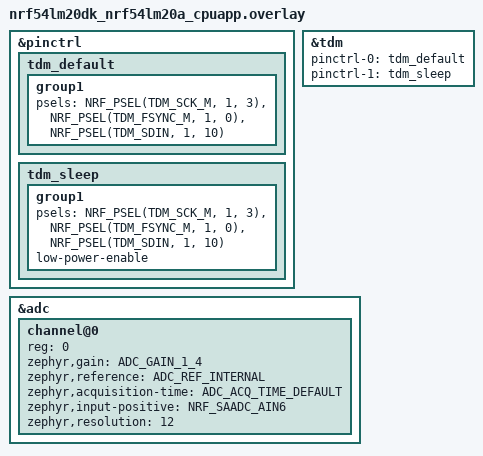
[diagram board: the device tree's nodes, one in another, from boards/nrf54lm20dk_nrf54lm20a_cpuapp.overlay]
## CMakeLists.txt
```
cmake_minimum_required(VERSION 3.20.0)
find_package(Zephyr REQUIRED HINTS $ENV{ZEPHYR_BASE})
project(kaitek_adc_test)
target_sources(app PRIVATE src/main.c)
```

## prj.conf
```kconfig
CONFIG_I2S=y
CONFIG_LOG=y
CONFIG_LOG_DEFAULT_LEVEL=3
CONFIG_MAIN_STACK_SIZE=4096
CONFIG_LOG_BACKEND_UART=y
CONFIG_UART_CONSOLE=y
CONFIG_ADC=y
CONFIG_ADC_NRFX_SAADC=y
```

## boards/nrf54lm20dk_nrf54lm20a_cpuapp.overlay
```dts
&pinctrl {
    tdm_default: tdm_default {
        group1 {
            psels = <NRF_PSEL(TDM_SCK_M, 1, 3)>,
                    <NRF_PSEL(TDM_FSYNC_M, 1, 0)>,
                    <NRF_PSEL(TDM_SDIN, 1, 10)>;
        };
    };
    tdm_sleep: tdm_sleep {
        group1 {
            psels = <NRF_PSEL(TDM_SCK_M, 1, 3)>,
                    <NRF_PSEL(TDM_FSYNC_M, 1, 0)>,
                    <NRF_PSEL(TDM_SDIN, 1, 10)>;
            low-power-enable;
        };
    };
};

&tdm {
    status = "okay";
    pinctrl-0 = <&tdm_default>;
    pinctrl-1 = <&tdm_sleep>;
    pinctrl-names = "default", "sleep";
};

&adc {
    status = "okay";
    #address-cells = <1>;
    #size-cells = <0>;

    channel@0 {
        reg = <0>;
        zephyr,gain = "ADC_GAIN_1_4";
        zephyr,reference = "ADC_REF_INTERNAL";
        zephyr,acquisition-time = <ADC_ACQ_TIME_DEFAULT>;
        zephyr,input-positive = <NRF_SAADC_AIN6>;  /* P1.04 */
        zephyr,resolution = <12>;
    };
};
```

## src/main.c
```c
#include <zephyr/kernel.h>
#include <zephyr/drivers/adc.h>
#include <zephyr/dt-bindings/adc/nrf-saadc.h>
#include <zephyr/logging/log.h>

LOG_MODULE_REGISTER(piezo_adc, LOG_LEVEL_INF);

#define ADC_NODE       DT_NODELABEL(adc)
#define ADC_CHANNEL    0
#define ADC_RESOLUTION 12
#define VREF_MV        600
#define VREF_GAIN      ADC_GAIN_1_4

static const struct device *adc_dev;
static int16_t sample_buffer;

static const struct adc_channel_cfg ch_cfg = {
    .gain             = ADC_GAIN_1_4,
    .reference        = ADC_REF_INTERNAL,
    .acquisition_time = ADC_ACQ_TIME_DEFAULT,
    .channel_id       = ADC_CHANNEL,
    .input_positive   = NRF_SAADC_AIN6,   /* P1.04 */
};

static struct adc_sequence sequence = {
    .channels    = BIT(ADC_CHANNEL),
    .buffer      = &sample_buffer,
    .buffer_size = sizeof(sample_buffer),
    .resolution  = ADC_RESOLUTION,
};

int main(void)
{
    int ret;

    adc_dev = DEVICE_DT_GET(ADC_NODE);
    if (!device_is_ready(adc_dev)) {
        printk("ADC device not ready\n");
        return -1;
    }
    printk("ADC device ready\n");

    ret = adc_channel_setup(adc_dev, &ch_cfg);
    if (ret < 0) {
        printk("adc_channel_setup failed: %d\n", ret);
        return ret;
    }
    printk("ADC canal 0 — P1.04 (AIN6) configure\n");

    while (1) {
        ret = adc_read(adc_dev, &sequence);
        if (ret < 0) {
            printk("adc_read failed: %d\n", ret);
            k_sleep(K_MSEC(100));
            continue;
        }

        int32_t mv = sample_buffer;
        adc_raw_to_millivolts(VREF_MV, VREF_GAIN, ADC_RESOLUTION, &mv);

        printk("RAW: %6d | Tension: %4d mV\n", sample_buffer, mv);

        k_sleep(K_MSEC(10));
    }

    return 0;
}
```
